AUTOSAR XML (schema 4-0-3)
standard types defined: uint8, Boolean, UInt16, UInt32, UInt8
package /AUTOSAR_Platform/DataConstrs
  range DC_Boolean: raw 0..1
  range DC_UInt16: raw 0..65535
  range DC_UInt8: raw 0..255
package /PATAC/Facility/DataTypes/Implementation
  compu method COMPU_Boolean: 0=FALSE, 1=TRUE
  unit NoUnit: factor-si-to-unit=1, offset-si-to-unit=0
package /PATAC/MSM/ComponentTypes
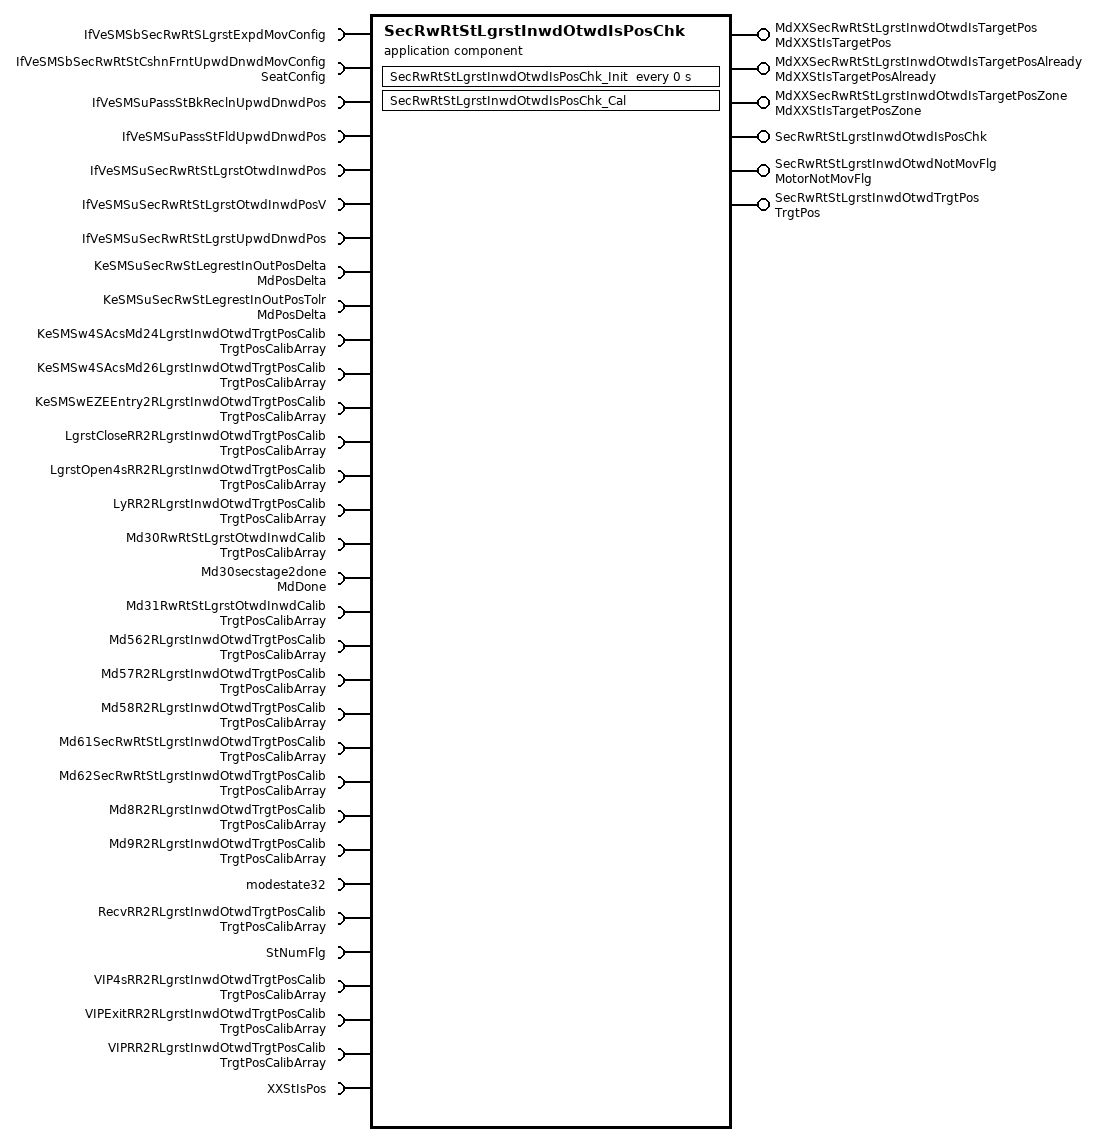
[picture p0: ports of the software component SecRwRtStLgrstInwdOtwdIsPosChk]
  application sw component type SecRwRtStLgrstInwdOtwdIsPosChk
    6 x provide port:
      MdXXSecRwRtStLgrstInwdOtwdIsTargetPos: nonqueued-sender-com-spec=data-element=MdXXStIsTargetPos/Val, provided-interface=MdXXStIsTargetPos
      MdXXSecRwRtStLgrstInwdOtwdIsTargetPosAlready: nonqueued-sender-com-spec=data-element=MdXXStIsTargetPosAlready/Val, provided-interface=MdXXStIsTargetPosAlready
      MdXXSecRwRtStLgrstInwdOtwdIsTargetPosZone: nonqueued-sender-com-spec=data-element=MdXXStIsTargetPosZone/Val, provided-interface=MdXXStIsTargetPosZone
      SecRwRtStLgrstInwdOtwdIsPosChk: server-com-spec{operation=Cal, queue-length=1}, provided-interface=SecRwRtStLgrstInwdOtwdIsPosChk
      SecRwRtStLgrstInwdOtwdNotMovFlg: nonqueued-sender-com-spec{data-element=MotorNotMovFlg/Val, init-value=0}, provided-interface=MotorNotMovFlg
      SecRwRtStLgrstInwdOtwdTrgtPos: nonqueued-sender-com-spec{data-element=TrgtPos/Val, init-value=4095}, provided-interface=TrgtPos
    32 x require port:
      IfVeSMSbSecRwRtSLgrstExpdMovConfig: nonqueued-receiver-com-spec{data-element=IfVeSMSbSecRwRtSLgrstExpdMovConfig/Val, filter=data-filter-type=ALWAYS, init-value=0}, required-interface=IfVeSMSbSecRwRtSLgrstExpdMovConfig
      IfVeSMSbSecRwRtStCshnFrntUpwdDnwdMovConfig: nonqueued-receiver-com-spec{data-element=SeatConfig/Val, filter=data-filter-type=ALWAYS, init-value=0}, required-interface=SeatConfig
      IfVeSMSuPassStBkReclnUpwdDnwdPos: nonqueued-receiver-com-spec{data-element=IfVeSMSuPassStBkReclnUpwdDnwdPos/Val, filter=data-filter-type=ALWAYS, init-value=0}, required-interface=IfVeSMSuPassStBkReclnUpwdDnwdPos
      IfVeSMSuPassStFldUpwdDnwdPos: nonqueued-receiver-com-spec{data-element=IfVeSMSuPassStFldUpwdDnwdPos/Val, filter=data-filter-type=ALWAYS, init-value=0}, required-interface=IfVeSMSuPassStFldUpwdDnwdPos
      IfVeSMSuSecRwRtStLgrstOtwdInwdPos: nonqueued-receiver-com-spec{data-element=IfVeSMSuSecRwRtStLgrstOtwdInwdPos/Val, filter=data-filter-type=ALWAYS, init-value=0}, required-interface=IfVeSMSuSecRwRtStLgrstOtwdInwdPos
      IfVeSMSuSecRwRtStLgrstOtwdInwdPosV: nonqueued-receiver-com-spec{data-element=IfVeSMSuSecRwRtStLgrstOtwdInwdPosV/Val, filter=data-filter-type=ALWAYS, init-value=0}, required-interface=IfVeSMSuSecRwRtStLgrstOtwdInwdPosV
      IfVeSMSuSecRwRtStLgrstUpwdDnwdPos: nonqueued-receiver-com-spec{data-element=IfVeSMSuSecRwRtStLgrstUpwdDnwdPos/Val, filter=data-filter-type=ALWAYS, init-value=0}, required-interface=IfVeSMSuSecRwRtStLgrstUpwdDnwdPos
      KeSMSuSecRwStLegrestInOutPosDelta: parameter-require-com-spec{init-value=150, parameter=Val}, required-interface=MdPosDelta
      KeSMSuSecRwStLegrestInOutPosTolr: parameter-require-com-spec{init-value=150, parameter=Val}, required-interface=MdPosDelta
      KeSMSw4SAcsMd24LgrstInwdOtwdTrgtPosCalib: nonqueued-receiver-com-spec{data-element=TrgtPosArray, filter=data-filter-type=ALWAYS, init-value=[4095, 4095, 4095]}, required-interface=TrgtPosCalibArray
      KeSMSw4SAcsMd26LgrstInwdOtwdTrgtPosCalib: nonqueued-receiver-com-spec{data-element=TrgtPosArray, filter=data-filter-type=ALWAYS, init-value=[4095, 4095, 4095]}, required-interface=TrgtPosCalibArray
      KeSMSwEZEEntry2RLgrstInwdOtwdTrgtPosCalib: nonqueued-receiver-com-spec{data-element=TrgtPosArray, filter=data-filter-type=ALWAYS, init-value=[4095, 4095, 4095]}, required-interface=TrgtPosCalibArray
      LgrstCloseRR2RLgrstInwdOtwdTrgtPosCalib: nonqueued-receiver-com-spec{data-element=TrgtPosArray, filter=data-filter-type=ALWAYS, init-value=[4095, 4095, 4095]}, required-interface=TrgtPosCalibArray
      LgrstOpen4sRR2RLgrstInwdOtwdTrgtPosCalib: nonqueued-receiver-com-spec{data-element=TrgtPosArray, filter=data-filter-type=ALWAYS, init-value=[4095, 4095, 4095]}, required-interface=TrgtPosCalibArray
      LyRR2RLgrstInwdOtwdTrgtPosCalib: nonqueued-receiver-com-spec{data-element=TrgtPosArray, filter=data-filter-type=ALWAYS, init-value=[4095, 4095, 4095]}, required-interface=TrgtPosCalibArray
      Md30RwRtStLgrstOtwdInwdCalib: nonqueued-receiver-com-spec{data-element=TrgtPosArray, filter=data-filter-type=ALWAYS, init-value=[4095, 4095, 4095]}, required-interface=TrgtPosCalibArray
      Md30secstage2done: nonqueued-receiver-com-spec{data-element=MdDone/Val, filter=data-filter-type=ALWAYS, init-value=0}, required-interface=MdDone
      Md31RwRtStLgrstOtwdInwdCalib: nonqueued-receiver-com-spec{data-element=TrgtPosArray, filter=data-filter-type=ALWAYS, init-value=[4095, 4095, 4095]}, required-interface=TrgtPosCalibArray
      Md562RLgrstInwdOtwdTrgtPosCalib: nonqueued-receiver-com-spec{data-element=TrgtPosArray, filter=data-filter-type=ALWAYS, init-value=[4095, 4095, 4095]}, required-interface=TrgtPosCalibArray
      Md57R2RLgrstInwdOtwdTrgtPosCalib: nonqueued-receiver-com-spec{data-element=TrgtPosArray, filter=data-filter-type=ALWAYS, init-value=[4095, 4095, 4095]}, required-interface=TrgtPosCalibArray
      Md58R2RLgrstInwdOtwdTrgtPosCalib: nonqueued-receiver-com-spec{data-element=TrgtPosArray, filter=data-filter-type=ALWAYS, init-value=[4095, 4095, 4095]}, required-interface=TrgtPosCalibArray
      Md61SecRwRtStLgrstInwdOtwdTrgtPosCalib: nonqueued-receiver-com-spec{data-element=TrgtPosArray, filter=data-filter-type=ALWAYS, init-value=[4095, 4095, 4095]}, required-interface=TrgtPosCalibArray
      Md62SecRwRtStLgrstInwdOtwdTrgtPosCalib: nonqueued-receiver-com-spec{data-element=TrgtPosArray, filter=data-filter-type=ALWAYS, init-value=[4095, 4095, 4095]}, required-interface=TrgtPosCalibArray
      Md8R2RLgrstInwdOtwdTrgtPosCalib: nonqueued-receiver-com-spec{data-element=TrgtPosArray, filter=data-filter-type=ALWAYS, init-value=[4095, 4095, 4095]}, required-interface=TrgtPosCalibArray
      Md9R2RLgrstInwdOtwdTrgtPosCalib: nonqueued-receiver-com-spec{data-element=TrgtPosArray, filter=data-filter-type=ALWAYS, init-value=[4095, 4095, 4095]}, required-interface=TrgtPosCalibArray
      modestate32: nonqueued-receiver-com-spec{data-element=modestate32/Val, filter=data-filter-type=ALWAYS, init-value=0}, required-interface=modestate32
      RecvRR2RLgrstInwdOtwdTrgtPosCalib: nonqueued-receiver-com-spec{data-element=TrgtPosArray, filter=data-filter-type=ALWAYS, init-value=[4095, 4095, 4095]}, required-interface=TrgtPosCalibArray
      StNumFlg: required-interface=StNumFlg
        required-com-specs:
          data-element=Is4s, filter=data-filter-type=ALWAYS, init-value=0
          data-element=Is6s, filter=data-filter-type=ALWAYS, init-value=0
          data-element=Is6s7s, filter=data-filter-type=ALWAYS, init-value=0
          data-element=Is7s, filter=data-filter-type=ALWAYS, init-value=0
      VIP4sRR2RLgrstInwdOtwdTrgtPosCalib: nonqueued-receiver-com-spec{data-element=TrgtPosArray, filter=data-filter-type=ALWAYS, init-value=[4095, 4095, 4095]}, required-interface=TrgtPosCalibArray
      VIPExitRR2RLgrstInwdOtwdTrgtPosCalib: nonqueued-receiver-com-spec{data-element=TrgtPosArray, filter=data-filter-type=ALWAYS, init-value=[4095, 4095, 4095]}, required-interface=TrgtPosCalibArray
      VIPRR2RLgrstInwdOtwdTrgtPosCalib: nonqueued-receiver-com-spec{data-element=TrgtPosArray, filter=data-filter-type=ALWAYS, init-value=[4095, 4095, 4095]}, required-interface=TrgtPosCalibArray
      XXStIsPos: client-com-spec=Get, required-interface=XXStIsPos
    behavior SecRwRtStLgrstInwdOtwdIsPosChk_InternalBehavior
      operation invoked event OIT_SecRwRtStLgrstInwdOtwdIsPosChk_Cal_SecRwRtStLgrstInwdOtwdIsPosChk_Cal: start-on-event=SecRwRtStLgrstInwdOtwdIsPosChk_Cal, operation=SecRwRtStLgrstInwdOtwdIsPosChk.Cal
      timing event SecRwRtStLgrstInwdOtwdIsPosChk_InitEvent: start-on-event=SecRwRtStLgrstInwdOtwdIsPosChk_Init, period=0
      runnable SecRwRtStLgrstInwdOtwdIsPosChk_Cal
        data-receive-point-by-arguments:
          32 x access:
            REC_IfVeSMSbSecRwRtSLgrstExpdMovConfig_Val: accessed-variable=IfVeSMSbSecRwRtSLgrstExpdMovConfig.Val
            REC_IfVeSMSbSecRwRtStCshnFrntUpwdDnwdMovConfig_Val: accessed-variable=IfVeSMSbSecRwRtStCshnFrntUpwdDnwdMovConfig.Val
            REC_IfVeSMSuPassStBkReclnUpwdDnwdPos_Val: accessed-variable=IfVeSMSuPassStBkReclnUpwdDnwdPos.Val
            REC_IfVeSMSuPassStFldUpwdDnwdPos_Val: accessed-variable=IfVeSMSuPassStFldUpwdDnwdPos.Val
            REC_IfVeSMSuSecRwRtStLgrstOtwdInwdPos_Val: accessed-variable=IfVeSMSuSecRwRtStLgrstOtwdInwdPos.Val
            REC_IfVeSMSuSecRwRtStLgrstOtwdInwdPosV_Val: accessed-variable=IfVeSMSuSecRwRtStLgrstOtwdInwdPosV.Val
            REC_IfVeSMSuSecRwRtStLgrstUpwdDnwdPos_Val: accessed-variable=IfVeSMSuSecRwRtStLgrstUpwdDnwdPos.Val
            REC_KeSMSw4SAcsMd24LgrstInwdOtwdTrgtPosCalib_TrgtPosArray: accessed-variable=KeSMSw4SAcsMd24LgrstInwdOtwdTrgtPosCalib.TrgtPosArray
            REC_KeSMSw4SAcsMd26LgrstInwdOtwdTrgtPosCalib_TrgtPosArray: accessed-variable=KeSMSw4SAcsMd26LgrstInwdOtwdTrgtPosCalib.TrgtPosArray
            REC_KeSMSwEZEEntry2RLgrstInwdOtwdTrgtPosCalib_TrgtPosArray: accessed-variable=KeSMSwEZEEntry2RLgrstInwdOtwdTrgtPosCalib.TrgtPosArray
            REC_LgrstCloseRR2RLgrstInwdOtwdTrgtPosCalib_TrgtPosArray: accessed-variable=LgrstCloseRR2RLgrstInwdOtwdTrgtPosCalib.TrgtPosArray
            REC_LgrstOpen4sRR2RLgrstInwdOtwdTrgtPosCalib_TrgtPosArray: accessed-variable=LgrstOpen4sRR2RLgrstInwdOtwdTrgtPosCalib.TrgtPosArray
            REC_LyRR2RLgrstInwdOtwdTrgtPosCalib_TrgtPosArray: accessed-variable=LyRR2RLgrstInwdOtwdTrgtPosCalib.TrgtPosArray
            REC_Md30RwRtStLgrstOtwdInwdCalib_TrgtPosArray: accessed-variable=Md30RwRtStLgrstOtwdInwdCalib.TrgtPosArray
            REC_Md30secstage2done_Val: accessed-variable=Md30secstage2done.Val
            REC_Md31RwRtStLgrstOtwdInwdCalib_TrgtPosArray: accessed-variable=Md31RwRtStLgrstOtwdInwdCalib.TrgtPosArray
            REC_Md562RLgrstInwdOtwdTrgtPosCalib_TrgtPosArray: accessed-variable=Md562RLgrstInwdOtwdTrgtPosCalib.TrgtPosArray
            REC_Md57R2RLgrstInwdOtwdTrgtPosCalib_TrgtPosArray: accessed-variable=Md57R2RLgrstInwdOtwdTrgtPosCalib.TrgtPosArray
            REC_Md58R2RLgrstInwdOtwdTrgtPosCalib_TrgtPosArray: accessed-variable=Md58R2RLgrstInwdOtwdTrgtPosCalib.TrgtPosArray
            REC_Md61SecRwRtStLgrstInwdOtwdTrgtPosCalib_TrgtPosArray: accessed-variable=Md61SecRwRtStLgrstInwdOtwdTrgtPosCalib.TrgtPosArray
            REC_Md62SecRwRtStLgrstInwdOtwdTrgtPosCalib_TrgtPosArray: accessed-variable=Md62SecRwRtStLgrstInwdOtwdTrgtPosCalib.TrgtPosArray
            REC_Md8R2RLgrstInwdOtwdTrgtPosCalib_TrgtPosArray: accessed-variable=Md8R2RLgrstInwdOtwdTrgtPosCalib.TrgtPosArray
            REC_Md9R2RLgrstInwdOtwdTrgtPosCalib_TrgtPosArray: accessed-variable=Md9R2RLgrstInwdOtwdTrgtPosCalib.TrgtPosArray
            REC_modestate32_Val: accessed-variable=modestate32.Val
            REC_RecvRR2RLgrstInwdOtwdTrgtPosCalib_TrgtPosArray: accessed-variable=RecvRR2RLgrstInwdOtwdTrgtPosCalib.TrgtPosArray
            REC_StNumFlg_Is4s: accessed-variable=StNumFlg.Is4s
            REC_StNumFlg_Is6s: accessed-variable=StNumFlg.Is6s
            REC_StNumFlg_Is6s7s: accessed-variable=StNumFlg.Is6s7s
            REC_StNumFlg_Is7s: accessed-variable=StNumFlg.Is7s
            REC_VIP4sRR2RLgrstInwdOtwdTrgtPosCalib_TrgtPosArray: accessed-variable=VIP4sRR2RLgrstInwdOtwdTrgtPosCalib.TrgtPosArray
            REC_VIPExitRR2RLgrstInwdOtwdTrgtPosCalib_TrgtPosArray: accessed-variable=VIPExitRR2RLgrstInwdOtwdTrgtPosCalib.TrgtPosArray
            REC_VIPRR2RLgrstInwdOtwdTrgtPosCalib_TrgtPosArray: accessed-variable=VIPRR2RLgrstInwdOtwdTrgtPosCalib.TrgtPosArray
        data-send-points:
          5 x access:
            SEND_MdXXSecRwRtStLgrstInwdOtwdIsTargetPos_Val: accessed-variable=MdXXSecRwRtStLgrstInwdOtwdIsTargetPos.Val
            SEND_MdXXSecRwRtStLgrstInwdOtwdIsTargetPosAlready_Val: accessed-variable=MdXXSecRwRtStLgrstInwdOtwdIsTargetPosAlready.Val
            SEND_MdXXSecRwRtStLgrstInwdOtwdIsTargetPosZone_Val: accessed-variable=MdXXSecRwRtStLgrstInwdOtwdIsTargetPosZone.Val
            SEND_SecRwRtStLgrstInwdOtwdNotMovFlg_Val: accessed-variable=SecRwRtStLgrstInwdOtwdNotMovFlg.Val
            SEND_SecRwRtStLgrstInwdOtwdTrgtPos_Val: accessed-variable=SecRwRtStLgrstInwdOtwdTrgtPos.Val
        parameter access PA_KeSMSuSecRwStLegrestInOutPosDelta_Val: accessed-parameter=KeSMSuSecRwStLegrestInOutPosDelta.Val
        parameter access PA_KeSMSuSecRwStLegrestInOutPosTolr_Val: accessed-parameter=KeSMSuSecRwStLegrestInOutPosTolr.Val
        sync call SC_XXStIsPos_Get: operation=XXStIsPos.Get, timeout=0
      runnable SecRwRtStLgrstInwdOtwdIsPosChk_Init
        parameter access PA_KeSMSuSecRwStLegrestInOutPosDelta_Val: accessed-parameter=KeSMSuSecRwStLegrestInOutPosDelta.Val
        parameter access PA_KeSMSuSecRwStLegrestInOutPosTolr_Val: accessed-parameter=KeSMSuSecRwStLegrestInOutPosTolr.Val
  swc implementation SecRwRtStLgrstInwdOtwdIsPosChk_Implementation: behavior=SecRwRtStLgrstInwdOtwdIsPosChk_InternalBehavior
    code-descriptors:
      code Default: artifact-descriptors=autosar-engineering-object={short-label=Default, category=SWSRC}
package /PATAC/MSM/ModeAdjust/CalPortInterface
  parameter interface MdPosDelta
    parameter data prototype Val: sw-calibration-access=READ-WRITE, type=UInt16
package /PATAC/MSM/ModeAdjust/DataType
  impl type TrgtPosCalibArray: category=ARRAY, sw-calibration-access=READ-ONLY, type-emitter=RTE  # 0:pos 1:max 2:min
    element Element: array-size=3, array-size-semantics=FIXED-SIZE, implementation-data-type=UInt16, invalid-value=0
package /PATAC/MSM/ModeAdjust/PortInterface
  client server interface SecRwRtStLgrstInwdOtwdIsPosChk
    operation Cal
  client server interface XXStIsPos
    operation Get
      8 x arg, all with server-argument-impl-policy=USE-ARGUMENT-TYPE:
        PosV: type=DataTypes/Boolean, direction=IN
        Pos: type=UInt16, direction=IN
        CalibArray: type=TrgtPosCalibArray, direction=IN
        Delta: type=UInt16, direction=IN
        Tolr: type=UInt16, direction=IN
        IsPos: type=DataTypes/Boolean, direction=OUT
        IsPosZone: type=DataTypes/Boolean, direction=OUT
        IsPosAlready: type=DataTypes/Boolean, direction=OUT
  10 x sender receiver interface:
    IfVeSMSbSecRwRtSLgrstExpdMovConfig: invalidation-policy{data-element=IfVeSMSbSecRwRtSLgrstExpdMovConfig/Val, handle-invalid=DONT-INVALIDATE}
      data Val: type=Implementation/Boolean
    IfVeSMSuPassStFldUpwdDnwdPos: invalidation-policy{data-element=IfVeSMSuPassStFldUpwdDnwdPos/Val, handle-invalid=DONT-INVALIDATE}
      data Val: type=UInt16
    MdDone: invalidation-policy{data-element=MdDone/Val, handle-invalid=DONT-INVALIDATE}
      data Val: type=UInt8
    MdXXStIsTargetPos: invalidation-policy{data-element=MdXXStIsTargetPos/Val, handle-invalid=DONT-INVALIDATE}
      data Val: type=UInt32
    MdXXStIsTargetPosAlready: invalidation-policy{data-element=MdXXStIsTargetPosAlready/Val, handle-invalid=DONT-INVALIDATE}
      data Val: type=UInt32
    MdXXStIsTargetPosZone: invalidation-policy{data-element=MdXXStIsTargetPosZone/Val, handle-invalid=DONT-INVALIDATE}
      data Val: type=UInt32
    modestate32: invalidation-policy{data-element=modestate32/Val, handle-invalid=DONT-INVALIDATE}
      data Val: type=UInt32
    MotorNotMovFlg: invalidation-policy{data-element=MotorNotMovFlg/Val, handle-invalid=DONT-INVALIDATE}
      data Val: type=Implementation/Boolean
    StNumFlg
      4 x data, all with type=Implementation/Boolean:
        Is4s
        Is6s
        Is6s7s
        Is7s
      invalidation-policys:
        data-element=Is4s, handle-invalid=DONT-INVALIDATE
        data-element=Is6s, handle-invalid=DONT-INVALIDATE
        data-element=Is6s7s, handle-invalid=DONT-INVALIDATE
        data-element=Is7s, handle-invalid=DONT-INVALIDATE
    TrgtPosCalibArray: invalidation-policy{data-element=TrgtPosArray, handle-invalid=DONT-INVALIDATE}
      data TrgtPosArray: type=TrgtPosCalibArray  # 0:Pos 1:Max 2:Min
package /PATAC/MSM/PortInterfaces
  6 x sender receiver interface:
    IfVeSMSuPassStBkReclnUpwdDnwdPos: invalidation-policy{data-element=IfVeSMSuPassStBkReclnUpwdDnwdPos/Val, handle-invalid=DONT-INVALIDATE}
      data Val: type=UInt16
    IfVeSMSuSecRwRtStLgrstOtwdInwdPos: invalidation-policy{data-element=IfVeSMSuSecRwRtStLgrstOtwdInwdPos/Val, handle-invalid=DONT-INVALIDATE}
      data Val: type=UInt16
    IfVeSMSuSecRwRtStLgrstOtwdInwdPosV: invalidation-policy{data-element=IfVeSMSuSecRwRtStLgrstOtwdInwdPosV/Val, handle-invalid=DONT-INVALIDATE}
      data Val: type=Implementation/Boolean
    IfVeSMSuSecRwRtStLgrstUpwdDnwdPos: invalidation-policy{data-element=IfVeSMSuSecRwRtStLgrstUpwdDnwdPos/Val, handle-invalid=DONT-INVALIDATE}
      data Val: type=UInt16
    SeatConfig: invalidation-policy{data-element=SeatConfig/Val, handle-invalid=DONT-INVALIDATE}
      data Val: type=Implementation/Boolean
    TrgtPos: invalidation-policy{data-element=TrgtPos/Val, handle-invalid=DONT-INVALIDATE}
      data Val: type=UInt16
